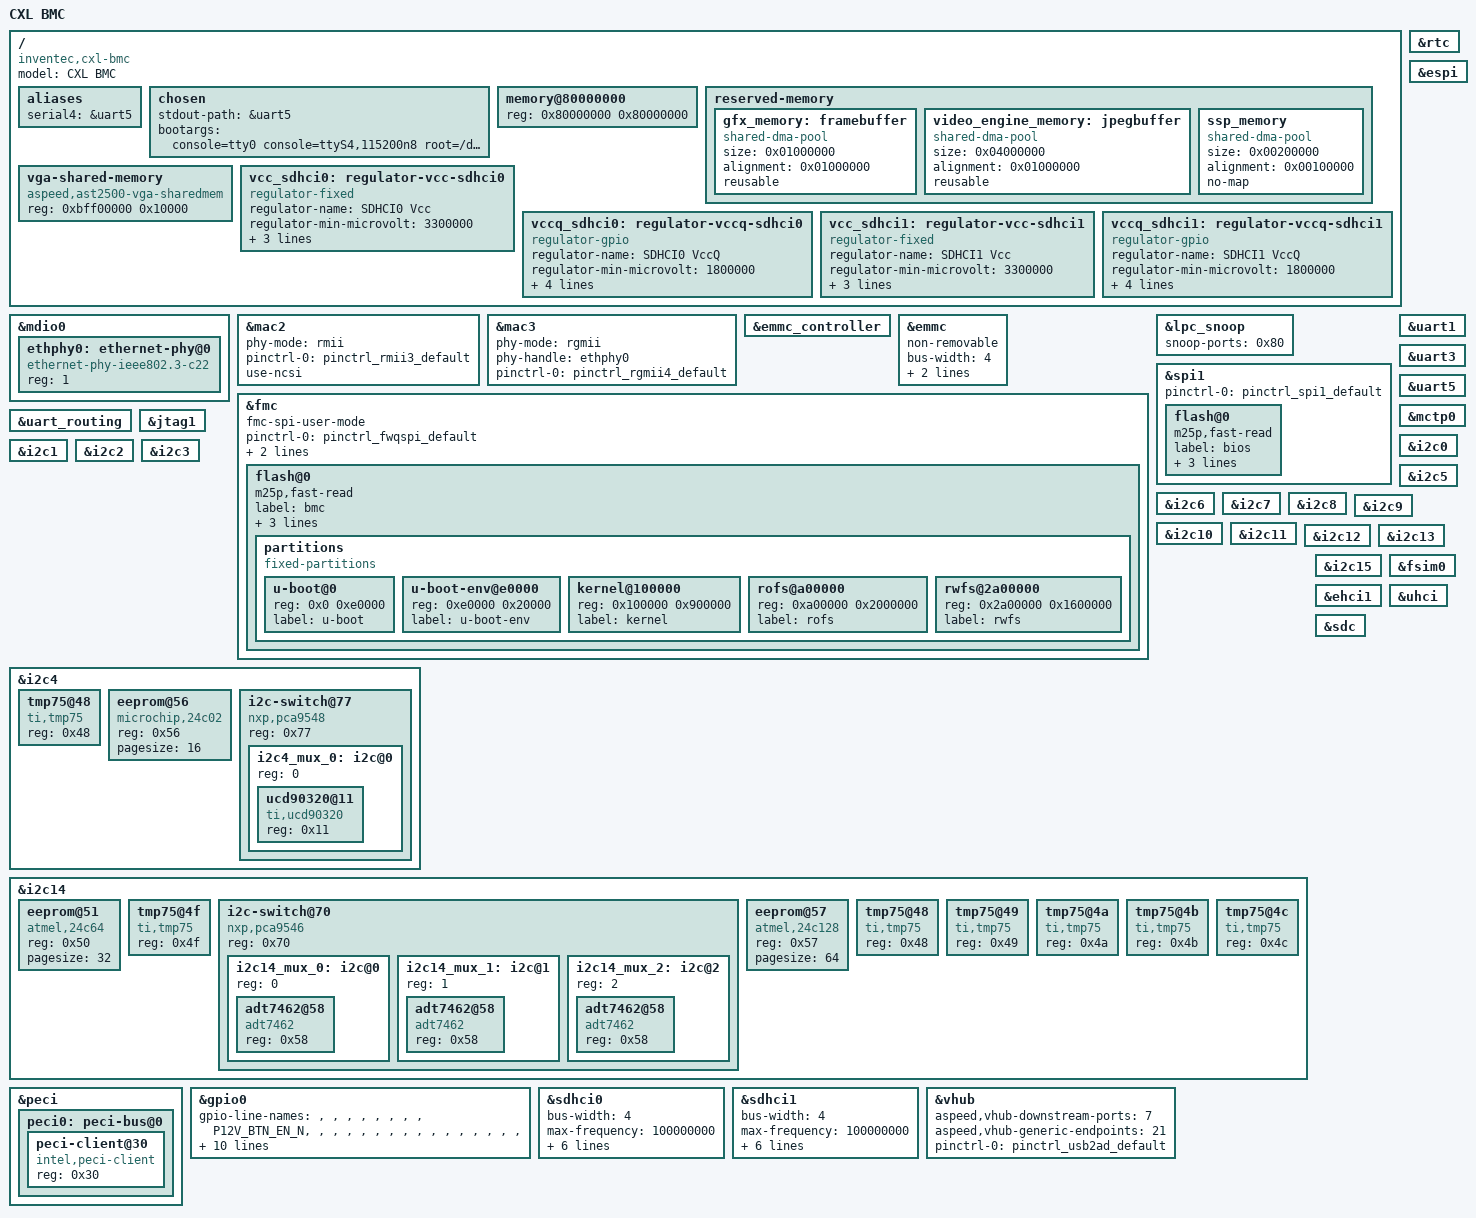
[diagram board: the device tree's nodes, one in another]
// SPDX-License-Identifier: GPL-2.0-or-later
// Copyright 2019 IBM Corp.

/dts-v1/;

#include "aspeed-g6.dtsi"
#include "aspeed-g6-pinctrl.dtsi"
#include <dt-bindings/i2c/i2c.h>
#include <dt-bindings/gpio/aspeed-gpio.h>

/ {
	model = "CXL BMC";
	compatible = "inventec,cxl-bmc", "aspeed,ast2600";

	aliases {
		serial4 = &uart5;
	};

	chosen {
		stdout-path = &uart5;
		bootargs = "console=tty0 console=ttyS4,115200n8 root=/dev/ram rw init=/linuxrc";
	};

	memory@80000000 {
		device_type = "memory";
		reg = <0x80000000 0x80000000>;
	};

	reserved-memory {
		#address-cells = <1>;
		#size-cells = <1>;
		ranges;

		gfx_memory: framebuffer {
			size = <0x01000000>;
			alignment = <0x01000000>;
			compatible = "shared-dma-pool";
			reusable;
		};

		video_engine_memory: jpegbuffer {
			size = <0x04000000>; /*64MB*/
			alignment = <0x01000000>;
			compatible = "shared-dma-pool";
			reusable;
		};

		ssp_memory: ssp_memory {
			size = <0x00200000>;
			alignment = <0x00100000>;
			compatible = "shared-dma-pool";
			no-map;
		};
#if 0
		espi_peripheral_memory: espi_peripheral_memory {
			no-map;
			reg = <0x98000000 0x04000000>; /* 64M */
			size = <0x01000000>;
			alignment = <0x01000000>;
			compatible = "shared-dma-pool";
			reusable;
		};
#endif
};

	vga-shared-memory {
		compatible = "aspeed,ast2500-vga-sharedmem";
		reg = <0xbff00000 0x10000>;
	};

	vcc_sdhci0: regulator-vcc-sdhci0 {
		compatible = "regulator-fixed";
		regulator-name = "SDHCI0 Vcc";
		regulator-min-microvolt = <3300000>;
		regulator-max-microvolt = <3300000>;
		gpios = <&gpio0 ASPEED_GPIO(V, 0) GPIO_ACTIVE_HIGH>;
		enable-active-high;
	};

	vccq_sdhci0: regulator-vccq-sdhci0 {
		compatible = "regulator-gpio";
		regulator-name = "SDHCI0 VccQ";
		regulator-min-microvolt = <1800000>;
		regulator-max-microvolt = <3300000>;
		gpios = <&gpio0 ASPEED_GPIO(V, 1) GPIO_ACTIVE_HIGH>;
		gpios-states = <1>;
		states = <3300000 1>,
			 <1800000 0>;
	};

	vcc_sdhci1: regulator-vcc-sdhci1 {
		compatible = "regulator-fixed";
		regulator-name = "SDHCI1 Vcc";
		regulator-min-microvolt = <3300000>;
		regulator-max-microvolt = <3300000>;
		gpios = <&gpio0 ASPEED_GPIO(V, 2) GPIO_ACTIVE_HIGH>;
		enable-active-high;
	};

	vccq_sdhci1: regulator-vccq-sdhci1 {
		compatible = "regulator-gpio";
		regulator-name = "SDHCI1 VccQ";
		regulator-min-microvolt = <1800000>;
		regulator-max-microvolt = <3300000>;
		gpios = <&gpio0 ASPEED_GPIO(V, 3) GPIO_ACTIVE_HIGH>;
		gpios-states = <1>;
		states = <3300000 1>,
			 <1800000 0>;
	};
};

&mdio0 {
	status = "okay";

	ethphy0: ethernet-phy@0 {
		compatible = "ethernet-phy-ieee802.3-c22";
		reg = <1>;
	};
};

&mac2 {
        status = "okay";
        pinctrl-names = "default";
        phy-mode = "rmii";
        pinctrl-0 = <&pinctrl_rmii3_default>;
        use-ncsi;
};

&mac3 {
	status = "okay";

	phy-mode = "rgmii";
	phy-handle = <&ethphy0>;

	pinctrl-names = "default";
	pinctrl-0 = <&pinctrl_rgmii4_default>;
};

&emmc_controller {
	status = "okay";
};

&emmc {
	non-removable;
	bus-width = <4>;
	max-frequency = <100000000>;
	clk-phase-mmc-hs200 = <9>, <225>;
};

&rtc {
	status = "okay";
};

&fmc {
	fmc-spi-user-mode;
	pinctrl-names = "default";
	pinctrl-0 = <&pinctrl_fwqspi_default>;
	timing-calibration-disabled;
	status = "okay";
	num-cs = <1>;
	flash@0 {
		status = "okay";
		m25p,fast-read;
		label = "bmc";
		spi-max-frequency = <33000000>;
		spi-tx-bus-width = <2>;
		spi-rx-bus-width = <2>;
		partitions {
			compatible = "fixed-partitions";
			#address-cells = <0x1>;
			#size-cells = <0x1>;

			u-boot@0 {
				reg = <0x0 0xe0000>;
				label = "u-boot";
			};

			u-boot-env@e0000 {
				reg = <0xe0000 0x20000>;
				label = "u-boot-env";
			};

			kernel@100000 {
				reg = <0x100000 0x900000>;
				label = "kernel";
			};

			rofs@a00000 {
				reg = <0xa00000 0x2000000>;
				label = "rofs";
			};

			rwfs@2a00000 {
				reg = <0x2a00000 0x1600000>;
				label = "rwfs";
			};
		};
	};
};

&lpc_snoop {
	status = "okay";
	snoop-ports = <0x80>;
};

&espi {
        status = "okay";
};

&spi1 {
	status = "okay";
	pinctrl-names = "default";
	pinctrl-0 = <&pinctrl_spi1_default>;
	flash@0 {
		status = "okay";
		m25p,fast-read;
		label = "bios";
		spi-max-frequency = <33000000>;
		spi-tx-bus-width = <1>;
		spi-rx-bus-width = <1>;
	};
};

&uart1 {
        status = "okay";
};

&uart3 {
        status = "okay";
};

&uart5 {
	status = "okay";
};

&uart_routing {
	status = "okay";
};

&mctp0 {
	status = "okay";
};

&jtag1 {
	status = "okay";
};

&i2c0 {
	status = "okay";
};

&i2c1 {
	status = "okay";
};

&i2c2 {
	status = "okay";
};

&i2c3 {
	status = "okay";
};

&i2c4 {
	status = "okay";

	tmp75@48 {
		compatible = "ti,tmp75";
		reg = <0x48>;
 	};

	 eeprom@56 {
		compatible = "microchip,24c02";
		reg = <0x56>;
		pagesize = <16>;
	};

	i2c-switch@77 {
		compatible = "nxp,pca9548";
		#address-cells = <1>;
		#size-cells = <0>;
		reg = <0x77>;

		i2c4_mux_0: i2c@0 {
			#address-cells = <1>;
			#size-cells = <0>;
			reg = <0>;

 			ucd90320@11 {
		  			compatible = "ti,ucd90320";
		  			reg = <0x11>;
 			};
		};
	};
};

&i2c5 {
	status = "okay";
};	

&i2c6 {
	status = "okay";
};

&i2c7 {
	status = "okay";
};

&i2c8 {
	status = "okay";
};

&i2c9 {
	status = "okay";
};

&i2c10 {
	status = "okay";
};

&i2c11 {
	status = "okay";
};

&i2c12 {
	status = "okay";
};

&i2c13 {
    status = "okay";
};

&i2c14 {
    status = "okay";

	/* CXL DCSCM_EEPROM*/
	eeprom@51 {
		compatible = "atmel,24c64";
		reg = <0x50>;
		pagesize = <32>;
		};

 	tmp75@4f {
		compatible = "ti,tmp75";
		reg = <0x4f>;
               	};

		i2c-switch@70 {
			compatible = "nxp,pca9546";
			#address-cells = <1>;
			#size-cells = <0>;
			reg = <0x70>;

                        i2c14_mux_0: i2c@0 {
                                            #address-cells = <1>;
                                            #size-cells = <0>;
                                            reg = <0>;

                                adt7462@58 {
                                            compatible = "adt7462";
                                            reg = <0x58>;
                                };
                        };

                        i2c14_mux_1: i2c@1 {
                                            #address-cells = <1>;
                                            #size-cells = <0>;
                                            reg = <1>;

                                adt7462@58 {
                                            compatible = "adt7462";
                                            reg = <0x58>;
                                };
                        };

                        i2c14_mux_2: i2c@2 {
                                            #address-cells = <1>;
                                            #size-cells = <0>;
                                            reg = <2>;

                                adt7462@58 {
                                            compatible = "adt7462";
                                            reg = <0x58>;
                                };
                        };

		};

	eeprom@57 {
		compatible = "atmel,24c128";
		reg = <0x57>;
		pagesize = <64>;
	};

	tmp75@48 {
		compatible = "ti,tmp75";
		reg = <0x48>;
	};

	tmp75@49 {
		compatible = "ti,tmp75";
		reg = <0x49>;
	};

	tmp75@4a {
		compatible = "ti,tmp75";
		reg = <0x4a>;
	};

	tmp75@4b {
		compatible = "ti,tmp75";
		reg = <0x4b>;
	};

	tmp75@4c {
		compatible = "ti,tmp75";
		reg = <0x4c>;
	};
};

&i2c15 {
	status = "okay";
};

&peci{
	peci0: peci-bus@0{
		status = "okay";

		peci-client@30 {
			compatible = "intel,peci-client";
			reg = <0x30>;
		};
	};
};

&gpio0 {
	status = "okay";
	gpio-line-names =
	/*A0-A7*/   "","","","","","","","",
	/*B0-B7*/   "P12V_BTN_EN_N","","","","","","","",
	/*C0-C7*/   "","","","","","","","",
	/*D0-D7*/   "","","","","","","","",
	/*E0-E7*/   "","","","","","","","",
	/*F0-F7*/   "","","","","","","","",
	/*G0-G7*/   "","","","","","","","",
	/*H0-H7*/   "","","","","","","","",
	/*I0-I7*/   "","","","","","","","",
	/*J0-J7*/   "","","","","","","","",
	/*K0-K7*/   "","","","","","","","",
	/*L0-L7*/   "","","","","","","","",
	/*M0-M7*/   "","","","","","","","",
	/*N0-N7*/   "","","","","","","","",
	/*O0-O7*/   "","","","","","","","",
	/*P0-P7*/   "","","","","","","","",
	/*Q0-Q7*/   "","","","","","","","",
	/*R0-R7*/   "","","","","","","","",
	/*S0-S7*/   "","","","","","","","",
	/*T0-T7*/   "","","","","","","","",
	/*U0-U7*/   "","","","","","","","",
	/*V0-V7*/   "","","","","","","","",
	/*W0-W7*/   "","","","","","","","",
	/*X0-X7*/   "","","","","","","","",
	/*Y0-Y7*/   "","","","","","","","",
	/*Z0-Z7*/   "","","","","","","","",
	/*AA0-AA7*/ "","","","","","","","",
	/*AB0-AB7*/ "","","","","","","","",
	/*AC0-AC7*/ "","","","","","","","";
};

&fsim0 {
	status = "okay";
};

&ehci1 {
	status = "okay";
};

&uhci {
	status = "okay";
};

&sdc {
	status = "okay";
};

/*
 * The signal voltage of sdhci0 and sdhci1 on AST2600-A2 EVB is able to be
 * toggled by GPIO pins.
 * In the reference design, GPIOV0 of AST2600-A2 EVB is connected to the
 * power load switch that provides 3.3v to sdhci0 vdd, GPIOV1 is connected to
 * a 1.8v and a 3.3v power load switch that provides signal voltage to
 * sdhci0 bus.
 * If GPIOV0 is active high, sdhci0 is enabled, otherwise, sdhci0 is disabled.
 * If GPIOV1 is active high, 3.3v power load switch is enabled, sdhci0 signal
 * voltage is 3.3v, otherwise, 1.8v power load switch will be enabled,
 * sdhci0 signal voltage becomes 1.8v.
 * AST2600-A2 EVB also supports toggling signal voltage for sdhci1.
 * The design is the same as sdhci0, it uses GPIOV2 as power-gpio and GPIOV3
 * as power-switch-gpio.
 */
&sdhci0 {
	status = "okay";
	bus-width = <4>;
	max-frequency = <100000000>;
	sdhci-drive-type = /bits/ 8 <3>;
	sdhci-caps-mask = <0x7 0x0>;
	sdhci,wp-inverted;
	vmmc-supply = <&vcc_sdhci0>;
	vqmmc-supply = <&vccq_sdhci0>;
	clk-phase-sd-hs = <7>, <200>;
};

&sdhci1 {
	status = "okay";
	bus-width = <4>;
	max-frequency = <100000000>;
	sdhci-drive-type = /bits/ 8 <3>;
	sdhci-caps-mask = <0x7 0x0>;
	sdhci,wp-inverted;
	vmmc-supply = <&vcc_sdhci1>;
	vqmmc-supply = <&vccq_sdhci1>;
	clk-phase-sd-hs = <7>, <200>;
};

&vhub {
	status = "okay";
	aspeed,vhub-downstream-ports = <7>;
	aspeed,vhub-generic-endpoints = <21>;
	pinctrl-names = "default";
	pinctrl-0 = <&pinctrl_usb2ad_default>;
};
